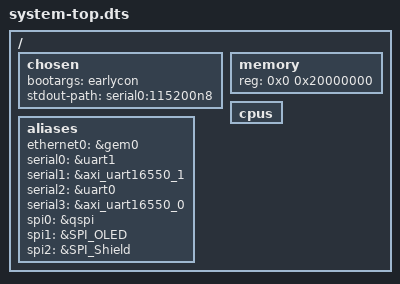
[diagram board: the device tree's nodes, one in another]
/*
 * CAUTION: This file is automatically generated by Xilinx.
 * Version:  
 * Today is: Thu Aug 31 12:42:08 2017
*/


/dts-v1/;
/include/ "zynq-7000.dtsi"
/include/ "pl.dtsi"
/include/ "pcw.dtsi"
/ {
	chosen {
		bootargs = "earlycon";
		stdout-path = "serial0:115200n8";
	};
	aliases {
		ethernet0 = &gem0;
		serial0 = &uart1;
		serial1 = &axi_uart16550_1;
		serial2 = &uart0;
		serial3 = &axi_uart16550_0;
		spi0 = &qspi;
		spi1 = &SPI_OLED;
		spi2 = &SPI_Shield;
	};
	memory {
		device_type = "memory";
		reg = <0x0 0x20000000>;
	};
	cpus {
	};
};
#include "system-user.dtsi"
